# WLR089U0 register map
Vendor: Microchip
Registers are 32-bit, read-write, reset 0x0 unless marked. A register's access mark holds for its fields unless they carry their own. Addresses are absolute, and some are shared; only a register's first bit layout is shown; [hi:lo] are bit positions; {n}, {i} and the like mark numbered series; <NAME> marks a mode.

## ADC
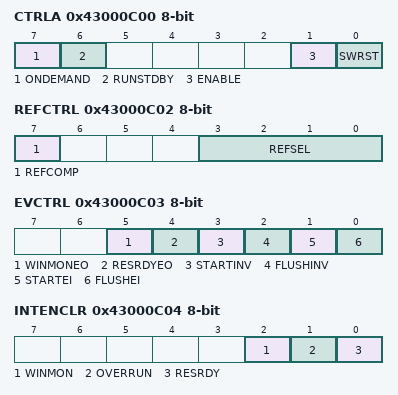
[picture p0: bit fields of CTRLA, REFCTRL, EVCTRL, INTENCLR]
0x43000C00 CTRLA 8-bit
  [7] ONDEMAND — On Demand Control
  [6] RUNSTDBY — Run during Standby
  [1] ENABLE
  [0] SWRST — Software Reset
0x43000C01 CTRLB 8-bit
  [2:0] PRESCALER — Prescaler Configuration
    0=DIV2 (Peripheral clock divided by 2); 1=DIV4 (Peripheral clock divided by 4); 2=DIV8 (Peripheral clock divided by 8); 3=DIV16 (Peripheral clock divided by 16); 4=DIV32 (Peripheral clock divided by 32); 5=DIV64 (Peripheral clock divided by 64); 6=DIV128 (Peripheral clock divided by 128); 7=DIV256 (Peripheral clock divided by 256)
0x43000C02 REFCTRL 8-bit
  [7] REFCOMP — Reference Buffer Offset Compensation Enable
  [3:0] REFSEL — Reference Selection
    0=INTREF (Internal Bandgap Reference); 1=INTVCC0 (1/1.6 VDDANA); 2=INTVCC1 (1/2 VDDANA); 3=AREFA (External Reference); 4=AREFB (External Reference); 5=INTVCC2 (VCCANA)
0x43000C03 EVCTRL 8-bit
  [5] WINMONEO — Window Monitor Event Out
  [4] RESRDYEO — Result Ready Event Out
  [3] STARTINV — Satrt Event Invert Enable
  [2] FLUSHINV — Flush Event Invert Enable
  [1] STARTEI — Start Conversion Event Input Enable
  [0] FLUSHEI — Flush Event Input Enable
0x43000C04 INTENCLR 8-bit
  [2] WINMON — Window Monitor Interrupt Disable
  [1] OVERRUN — Overrun Interrupt Disable
  [0] RESRDY — Result Ready Interrupt Disable
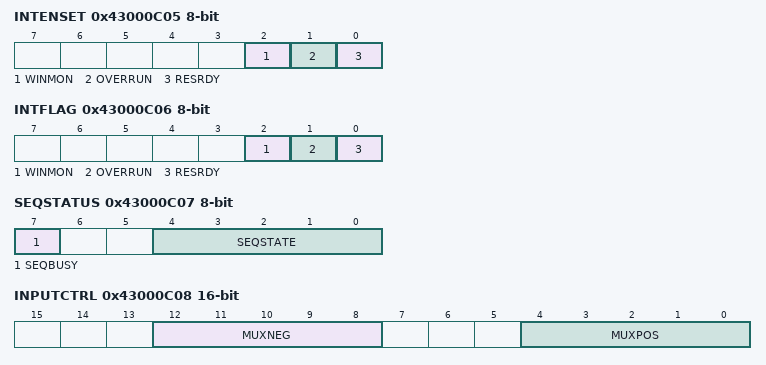
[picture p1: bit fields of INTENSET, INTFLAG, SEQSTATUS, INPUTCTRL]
0x43000C05 INTENSET 8-bit
  [2] WINMON — Window Monitor Interrupt Enable
  [1] OVERRUN — Overrun Interrupt Enable
  [0] RESRDY — Result Ready Interrupt Enable
0x43000C06 INTFLAG 8-bit
  [2] WINMON — Window Monitor Interrupt Flag
  [1] OVERRUN — Overrun Interrupt Flag
  [0] RESRDY — Result Ready Interrupt Flag
0x43000C07 SEQSTATUS 8-bit ro
  [7] SEQBUSY — Sequence Busy
  [4:0] SEQSTATE — Sequence State
0x43000C08 INPUTCTRL 16-bit
  [12:8] MUXNEG — Negative Mux Input Selection
    {v}=AIN{v} (ADC AIN{v} Pin) (v=0..7); 24=GND (Internal ground)
  [4:0] MUXPOS — Positive Mux Input Selection
    {v}=AIN{v} (ADC AIN{v} Pin) (v=0..19); 24=TEMP (Temperature Sensor); 25=BANDGAP (Bandgap Voltage); 26=SCALEDCOREVCC (1/4 Scaled Core Supply); 27=SCALEDIOVCC (1/4 Scaled I/O Supply); 28=DAC (DAC Output); 29=SCALEDVBAT (1/4 Scaled VBAT Supply); 30=OPAMP01 (OPAMP0 or OPAMP1 output); 31=OPAMP2 (OPAMP2 output)
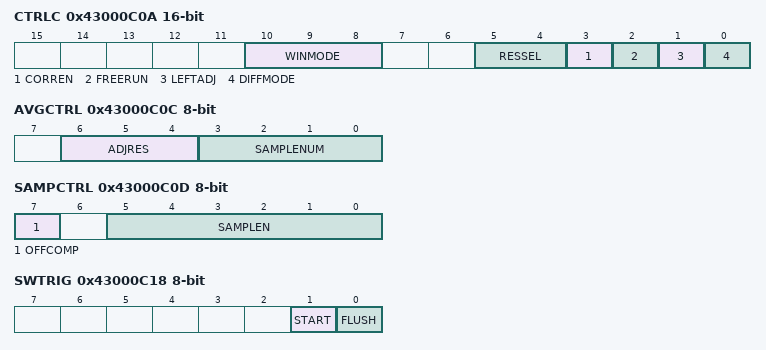
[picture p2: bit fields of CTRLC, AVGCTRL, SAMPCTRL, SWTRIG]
0x43000C0A CTRLC 16-bit
  [10:8] WINMODE — Window Monitor Mode
    0=DISABLE (No window mode (default)); 1=MODE1 (RESULT > WINLT); 2=MODE2 (RESULT < WINUT); 3=MODE3 (WINLT < RESULT < WINUT); 4=MODE4 (!(WINLT < RESULT < WINUT))
  [5:4] RESSEL — Conversion Result Resolution
    0=12BIT (12-bit result); 1=16BIT (For averaging mode output); 2=10BIT (10-bit result); 3=8BIT (8-bit result)
  [3] CORREN — Digital Correction Logic Enable
  [2] FREERUN — Free Running Mode
  [1] LEFTADJ — Left-Adjusted Result
  [0] DIFFMODE — Differential Mode
0x43000C0C AVGCTRL 8-bit
  [6:4] ADJRES — Adjusting Result / Division Coefficient
  [3:0] SAMPLENUM — Number of Samples to be Collected
    0=1 sample; 1=2 samples; 2=4 samples; 3=8 samples; 4=16 samples; 5=32 samples; 6=64 samples; 7=128 samples; 8=256 samples; 9=512 samples; 10=1024 samples
0x43000C0D SAMPCTRL 8-bit
  [7] OFFCOMP — Comparator Offset Compensation Enable
  [5:0] SAMPLEN — Sampling Time Length
0x43000C0E WINLT 16-bit
  [15:0] WINLT — Window Lower Threshold
0x43000C10 WINUT 16-bit
  [15:0] WINUT — Window Upper Threshold
0x43000C12 GAINCORR 16-bit
  [11:0] GAINCORR — Gain Correction Value
0x43000C14 OFFSETCORR 16-bit
  [11:0] OFFSETCORR — Offset Correction Value
0x43000C18 SWTRIG 8-bit
  [1] START — Start ADC Conversion
  [0] FLUSH — ADC Flush
0x43000C1C DBGCTRL 8-bit
  [0] DBGRUN — Debug Run
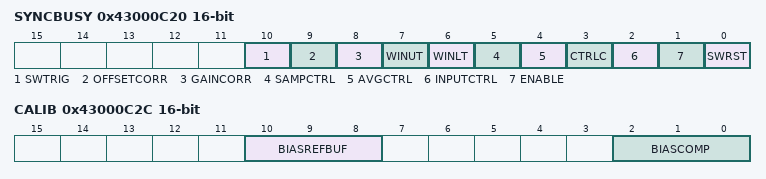
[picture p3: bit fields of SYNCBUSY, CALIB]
0x43000C20 SYNCBUSY 16-bit ro
  [10] SWTRIG — SWTRG Synchronization Busy
  [9] OFFSETCORR — OFFSETCTRL Synchronization Busy
  [8] GAINCORR — GAINCORR Synchronization Busy
  [7] WINUT — WINUT Synchronization Busy
  [6] WINLT — WINLT Synchronization Busy
  [5] SAMPCTRL — SAMPCTRL Synchronization Busy
  [4] AVGCTRL — AVGCTRL Synchronization Busy
  [3] CTRLC — CTRLC Synchronization Busy
  [2] INPUTCTRL — INPUTCTRL Synchronization Busy
  [1] ENABLE — ENABLE Synchronization Busy
  [0] SWRST — SWRST Synchronization Busy
0x43000C24 RESULT 16-bit ro
  [15:0] RESULT — Result Value
0x43000C28 SEQCTRL
  [31:0] SEQEN — Enable Positive Input in the Sequence
0x43000C2C CALIB 16-bit
  [10:8] BIASREFBUF — Bias Reference Buffer Scaling
  [2:0] BIASCOMP — Bias Comparator Scaling
